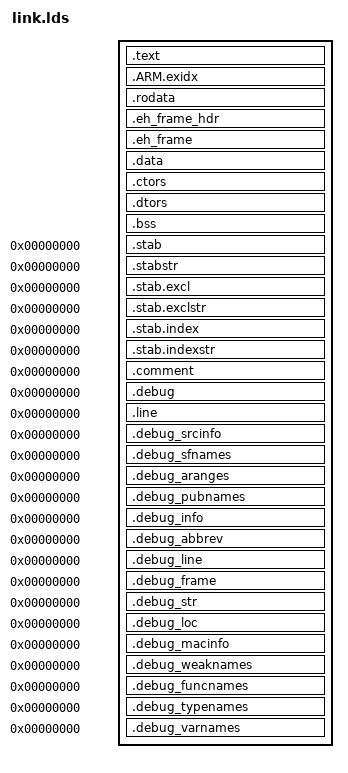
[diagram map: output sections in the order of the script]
/*
 * Copyright (c) 2006-2021, RT-Thread Development Team
 *
 * SPDX-License-Identifier: Apache-2.0
 *
 * Change Logs:
 * 2017-5-30     bernard       first version
 */

/* _EL1_STACK_SIZE = DEFINED(_EL1_STACK_SIZE) ? _EL1_STACK_SIZE : 0x20000; */

SECTIONS
{
    . = 0x8000;
    . = ALIGN(4096);
    .text :
    {
        KEEP(*(.text.entrypoint))       /* The entry point */
        *(.vectors)
        *(.text)                        /* remaining code */
        *(.text.*)                      /* remaining code */

        *(.rodata)                      /* read-only data (constants) */
        *(.rodata*)
        *(.glue_7)
        *(.glue_7t)
        *(.gnu.linkonce.t*)

        *(COMMON)

        /* section information for finsh shell */
        . = ALIGN(16);
        __fsymtab_start = .;
        KEEP(*(FSymTab))
        __fsymtab_end = .;
        . = ALIGN(16);
        __vsymtab_start = .;
        KEEP(*(VSymTab))
        __vsymtab_end = .;
        . = ALIGN(16);

        /* section information for initial. */
        . = ALIGN(16);
        __rt_init_start = .;
        KEEP(*(SORT(.rti_fn*)))
        __rt_init_end = .;
        . = ALIGN(16);

        . = ALIGN(16);
        _etext = .;
    }

    __exidx_start = .;
    .ARM.exidx   : { *(.ARM.exidx* .gnu.linkonce.armexidx.*) }
    __exidx_end = .;

    __rodata_start = .;
    .rodata   : { *(.rodata) *(.rodata.*) }
    __rodata_end = .;

    .eh_frame_hdr :
    {
         *(.eh_frame_hdr)
         *(.eh_frame_entry)
    }
    .eh_frame : ONLY_IF_RO { KEEP (*(.eh_frame)) }

    . = ALIGN(16);
    .data :
    {
     *(.data)
     *(.data.*)

     *(.data1)
     *(.data1.*)

     . = ALIGN(16);
     _gp = ABSOLUTE(.);     /* Base of small data */

     *(.sdata)
     *(.sdata.*)
    }

    . = ALIGN(16);
    .ctors :
    {
        PROVIDE(__ctors_start__ = .);
        KEEP(*(SORT(.ctors.*)))
        KEEP(*(.ctors))
        PROVIDE(__ctors_end__ = .);
    }

    .dtors :
    {
        PROVIDE(__dtors_start__ = .);
        KEEP(*(SORT(.dtors.*)))
        KEEP(*(.dtors))
        PROVIDE(__dtors_end__ = .);
    }

    . = ALIGN(16);
    .bss :
    {
        PROVIDE(__bss_start = .);
        *(.bss)
        *(.bss.*)
        *(.dynbss)

        PROVIDE(__bss_end = .);
    }
    _end = .;

    /* Stabs debugging sections.  */
    .stab          0 : { *(.stab) }
    .stabstr       0 : { *(.stabstr) }
    .stab.excl     0 : { *(.stab.excl) }
    .stab.exclstr  0 : { *(.stab.exclstr) }
    .stab.index    0 : { *(.stab.index) }
    .stab.indexstr 0 : { *(.stab.indexstr) }
    .comment       0 : { *(.comment) }
    /* DWARF debug sections.
     * Symbols in the DWARF debugging sections are relative to the beginning
     * of the section so we begin them at 0.  */
    /* DWARF 1 */
    .debug          0 : { *(.debug) }
    .line           0 : { *(.line) }
    /* GNU DWARF 1 extensions */
    .debug_srcinfo  0 : { *(.debug_srcinfo) }
    .debug_sfnames  0 : { *(.debug_sfnames) }
    /* DWARF 1.1 and DWARF 2 */
    .debug_aranges  0 : { *(.debug_aranges) }
    .debug_pubnames 0 : { *(.debug_pubnames) }
    /* DWARF 2 */
    .debug_info     0 : { *(.debug_info .gnu.linkonce.wi.*) }
    .debug_abbrev   0 : { *(.debug_abbrev) }
    .debug_line     0 : { *(.debug_line) }
    .debug_frame    0 : { *(.debug_frame) }
    .debug_str      0 : { *(.debug_str) }
    .debug_loc      0 : { *(.debug_loc) }
    .debug_macinfo  0 : { *(.debug_macinfo) }
    /* SGI/MIPS DWARF 2 extensions */
    .debug_weaknames 0 : { *(.debug_weaknames) }
    .debug_funcnames 0 : { *(.debug_funcnames) }
    .debug_typenames 0 : { *(.debug_typenames) }
    .debug_varnames  0 : { *(.debug_varnames) }
}

__bss_size = (__bss_end - __bss_start)>>3;
